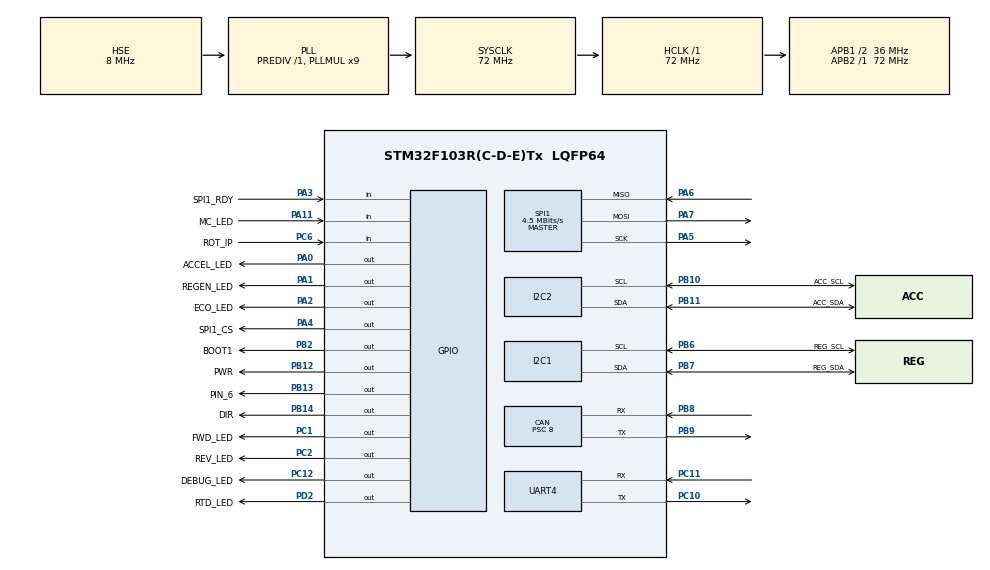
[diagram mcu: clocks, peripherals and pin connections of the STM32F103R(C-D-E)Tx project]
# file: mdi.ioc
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CAN.ABOM=ENABLE
CAN.BS1=CAN_BS1_4TQ
CAN.BS2=CAN_BS2_4TQ
CAN.CalculateBaudRate=500000
CAN.CalculateTimeBit=2000
CAN.CalculateTimeQuantum=222.22222222222223
CAN.NART=ENABLE
CAN.Prescaler=8
CAN.SJW=CAN_SJW_2TQ
Mcu.Family=STM32F1
Mcu.Name=STM32F103R(C-D-E)Tx
Mcu.Package=LQFP64
NVIC.PriorityGroup=NVIC_PRIORITYGROUP_4
NVIC.USB_LP_CAN1_RX0_IRQn=true\:0\:0\:false\:false\:true\:true\:true\:true
PA0-WKUP.GPIO_Label=ACCEL_LED
PA0-WKUP.Signal=GPIO_Output
PA1.GPIO_Label=REGEN_LED
PA1.Signal=GPIO_Output
PA11.GPIO_Label=MC_LED
PA11.Signal=GPIO_Input
PA13.Mode=Trace_Asynchronous_SW
PA13.Signal=SYS_JTMS-SWDIO
PA14.Mode=Trace_Asynchronous_SW
PA14.Signal=SYS_JTCK-SWCLK
PA2.GPIO_Label=ECO_LED
PA2.Signal=GPIO_Output
PA3.GPIO_Label=SPI1_RDY
PA3.Signal=GPIO_Input
PA4.GPIO_Label=SPI1_CS
PA4.PinState=GPIO_PIN_SET
PA4.Signal=GPIO_Output
PA5.Mode=Full_Duplex_Master
PA5.Signal=SPI1_SCK
PA6.Mode=Full_Duplex_Master
PA6.Signal=SPI1_MISO
PA7.Mode=Full_Duplex_Master
PA7.Signal=SPI1_MOSI
PB10.GPIO_Label=ACC_SCL
PB10.Mode=I2C
PB10.Signal=I2C2_SCL
PB11.GPIO_Label=ACC_SDA
PB11.Mode=I2C
PB11.Signal=I2C2_SDA
PB12.GPIO_Label=PWR
PB12.GPIO_ModeDefaultOutputPP=GPIO_MODE_OUTPUT_OD
PB12.GPIO_PuPd=GPIO_NOPULL
PB12.Signal=GPIO_Output
PB13.GPIO_Label=PIN_6
PB13.Signal=GPIO_Output
PB14.GPIO_Label=DIR
PB14.GPIO_ModeDefaultOutputPP=GPIO_MODE_OUTPUT_OD
PB14.GPIO_PuPd=GPIO_NOPULL
PB14.Signal=GPIO_Output
PB2.GPIO_Label=BOOT1
PB2.Signal=GPIO_Output
PB3.Mode=Trace_Asynchronous_SW
PB3.Signal=SYS_JTDO-TRACESWO
PB6.GPIO_Label=REG_SCL
PB6.Mode=I2C
PB6.Signal=I2C1_SCL
PB7.GPIO_Label=REG_SDA
PB7.Mode=I2C
PB7.Signal=I2C1_SDA
PB8.Mode=CAN_Activate
PB8.Signal=CAN_RX
PB9.Mode=CAN_Activate
PB9.Signal=CAN_TX
PC1.GPIO_Label=FWD_LED
PC1.Signal=GPIO_Output
PC10.Mode=Asynchronous
PC10.Signal=UART4_TX
PC11.Mode=Asynchronous
PC11.Signal=UART4_RX
PC12.GPIO_Label=DEBUG_LED
PC12.Signal=GPIO_Output
PC2.GPIO_Label=REV_LED
PC2.Signal=GPIO_Output
PC6.GPIO_Label=ROT_IP
PC6.Signal=GPIO_Input
PD0-OSC_IN.Mode=HSE-External-Oscillator
PD0-OSC_IN.Signal=RCC_OSC_IN
PD1-OSC_OUT.Mode=HSE-External-Oscillator
PD1-OSC_OUT.Signal=RCC_OSC_OUT
PD2.GPIO_Label=RTD_LED
PD2.Signal=GPIO_Output
ProjectManager.HeapSize=0x200
ProjectManager.StackSize=0x400
ProjectManager.TargetToolchain=CMake
RCC.AHBFreq_Value=72000000
RCC.APB1CLKDivider=RCC_HCLK_DIV2
RCC.APB1Freq_Value=36000000
RCC.APB1TimFreq_Value=72000000
RCC.APB2Freq_Value=72000000
RCC.APB2TimFreq_Value=72000000
RCC.HCLKFreq_Value=72000000
RCC.PLLMUL=RCC_PLL_MUL9
RCC.PLLSourceVirtual=RCC_PLLSOURCE_HSE
RCC.SYSCLKFreq_VALUE=72000000
RCC.SYSCLKSource=RCC_SYSCLKSOURCE_PLLCLK
RCC.USBFreq_Value=72000000
SPI1.BaudRatePrescaler=SPI_BAUDRATEPRESCALER_16
SPI1.CLKPhase=SPI_PHASE_2EDGE
SPI1.CLKPolarity=SPI_POLARITY_LOW
SPI1.CalculateBaudRate=4.5 MBits/s
SPI1.Direction=SPI_DIRECTION_2LINES
SPI1.Mode=SPI_MODE_MASTER
SPI1.VirtualType=VM_MASTER
UART4.VirtualMode=Asynchronous
VP_IWDG_VS_IWDG.Mode=IWDG_Activate
board=custom

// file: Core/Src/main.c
/* USER CODE BEGIN Header */
/**
  ******************************************************************************
  * @file           : main.c
  * @brief          : Main program body
  ******************************************************************************
  * @attention
  *
  * Copyright (c) 2026 STMicroelectronics.
  * All rights reserved.
  *
  * This software is licensed under terms that can be found in the LICENSE file
  * in the root directory of this software component.
  * If no LICENSE file comes with this software, it is provided AS-IS.
  *
  ******************************************************************************
  */
/* USER CODE END Header */
#include "main.h"

/* USER CODE BEGIN Includes */
#include "tasks.h"
#include "iwdg_common.h"

/* USER CODE END Includes */

CAN_HandleTypeDef hcan;

I2C_HandleTypeDef hi2c1;
I2C_HandleTypeDef hi2c2;

IWDG_HandleTypeDef hiwdg;

SPI_HandleTypeDef hspi1;

UART_HandleTypeDef huart4;

void SystemClock_Config(void);
static void MX_GPIO_Init(void);
static void MX_CAN_Init(void);
static void MX_I2C1_Init(void);
static void MX_I2C2_Init(void);
static void MX_SPI1_Init(void);
static void MX_UART4_Init(void);
static void MX_IWDG_Init(void);

int main(void)
{

  /* MCU Configuration--------------------------------------------------------*/

  /* Reset of all peripherals, Initializes the Flash interface and the Systick. */
  HAL_Init();

  /* Configure the system clock */
  SystemClock_Config();

  /* Initialize all configured peripherals */
  MX_GPIO_Init();
  MX_CAN_Init();
  MX_I2C1_Init();
  MX_I2C2_Init();
  MX_SPI1_Init();
  MX_UART4_Init();
  #ifndef DEBUG
  MX_IWDG_Init();
  #endif
  /* USER CODE BEGIN 2 */
  AppMain();
  /* USER CODE END 2 */

  /* Infinite loop */
  while (1)
  {

  }
}

void SystemClock_Config(void)
{
  RCC_OscInitTypeDef RCC_OscInitStruct = {0};
  RCC_ClkInitTypeDef RCC_ClkInitStruct = {0};

  /** Initializes the RCC Oscillators according to the specified parameters
  * in the RCC_OscInitTypeDef structure.
  */
  RCC_OscInitStruct.OscillatorType = RCC_OSCILLATORTYPE_LSI|RCC_OSCILLATORTYPE_HSE;
  RCC_OscInitStruct.HSEState = RCC_HSE_ON;
  RCC_OscInitStruct.HSEPredivValue = RCC_HSE_PREDIV_DIV1;
  RCC_OscInitStruct.HSIState = RCC_HSI_ON;
  RCC_OscInitStruct.LSIState = RCC_LSI_ON;
  RCC_OscInitStruct.PLL.PLLState = RCC_PLL_ON;
  RCC_OscInitStruct.PLL.PLLSource = RCC_PLLSOURCE_HSE;
  RCC_OscInitStruct.PLL.PLLMUL = RCC_PLL_MUL9;
  if (HAL_RCC_OscConfig(&RCC_OscInitStruct) != HAL_OK)
  {
    Error_Handler();
  }

  /** Initializes the CPU, AHB and APB buses clocks
  */
  RCC_ClkInitStruct.ClockType = RCC_CLOCKTYPE_HCLK|RCC_CLOCKTYPE_SYSCLK
                              |RCC_CLOCKTYPE_PCLK1|RCC_CLOCKTYPE_PCLK2;
  RCC_ClkInitStruct.SYSCLKSource = RCC_SYSCLKSOURCE_PLLCLK;
  RCC_ClkInitStruct.AHBCLKDivider = RCC_SYSCLK_DIV1;
  RCC_ClkInitStruct.APB1CLKDivider = RCC_HCLK_DIV2;
  RCC_ClkInitStruct.APB2CLKDivider = RCC_HCLK_DIV1;

  if (HAL_RCC_ClockConfig(&RCC_ClkInitStruct, FLASH_LATENCY_2) != HAL_OK)
  {
    Error_Handler();
  }
}

static void MX_CAN_Init(void)
{

  hcan.Instance = CAN1;
  hcan.Init.Prescaler = 8;
  hcan.Init.Mode = CAN_MODE_NORMAL;
  hcan.Init.SyncJumpWidth = CAN_SJW_2TQ;
  hcan.Init.TimeSeg1 = CAN_BS1_4TQ;
  hcan.Init.TimeSeg2 = CAN_BS2_4TQ;
  hcan.Init.TimeTriggeredMode = DISABLE;
  hcan.Init.AutoBusOff = ENABLE;
  hcan.Init.AutoWakeUp = DISABLE;
  hcan.Init.AutoRetransmission = ENABLE;
  hcan.Init.ReceiveFifoLocked = DISABLE;
  hcan.Init.TransmitFifoPriority = DISABLE;
  if (HAL_CAN_Init(&hcan) != HAL_OK)
  {
    Error_Handler();
  }

}

static void MX_I2C1_Init(void)
{

  hi2c1.Instance = I2C1;
  hi2c1.Init.ClockSpeed = 100000;
  hi2c1.Init.DutyCycle = I2C_DUTYCYCLE_2;
  hi2c1.Init.OwnAddress1 = 0;
  hi2c1.Init.AddressingMode = I2C_ADDRESSINGMODE_7BIT;
  hi2c1.Init.DualAddressMode = I2C_DUALADDRESS_DISABLE;
  hi2c1.Init.OwnAddress2 = 0;
  hi2c1.Init.GeneralCallMode = I2C_GENERALCALL_DISABLE;
  hi2c1.Init.NoStretchMode = I2C_NOSTRETCH_DISABLE;
  if (HAL_I2C_Init(&hi2c1) != HAL_OK)
  {
    Error_Handler();
  }

}

static void MX_I2C2_Init(void)
{

  hi2c2.Instance = I2C2;
  hi2c2.Init.ClockSpeed = 100000;
  hi2c2.Init.DutyCycle = I2C_DUTYCYCLE_2;
  hi2c2.Init.OwnAddress1 = 0;
  hi2c2.Init.AddressingMode = I2C_ADDRESSINGMODE_7BIT;
  hi2c2.Init.DualAddressMode = I2C_DUALADDRESS_DISABLE;
  hi2c2.Init.OwnAddress2 = 0;
  hi2c2.Init.GeneralCallMode = I2C_GENERALCALL_DISABLE;
  hi2c2.Init.NoStretchMode = I2C_NOSTRETCH_DISABLE;
  if (HAL_I2C_Init(&hi2c2) != HAL_OK)
  {
    Error_Handler();
  }

}

static void MX_IWDG_Init(void)
{

  hiwdg.Instance = IWDG;
  hiwdg.Init.Prescaler = IWDG_PRESCALER_4;
  hiwdg.Init.Reload = 4095;
  if (HAL_IWDG_Init(&hiwdg) != HAL_OK)
  {
    Error_Handler();
  }

}

static void MX_SPI1_Init(void)
{

  /* SPI1 parameter configuration*/
  hspi1.Instance = SPI1;
  hspi1.Init.Mode = SPI_MODE_MASTER;
  hspi1.Init.Direction = SPI_DIRECTION_2LINES;
  hspi1.Init.DataSize = SPI_DATASIZE_8BIT;
  hspi1.Init.CLKPolarity = SPI_POLARITY_LOW;
  hspi1.Init.CLKPhase = SPI_PHASE_2EDGE;
  hspi1.Init.NSS = SPI_NSS_SOFT;
  hspi1.Init.BaudRatePrescaler = SPI_BAUDRATEPRESCALER_16;
  hspi1.Init.FirstBit = SPI_FIRSTBIT_MSB;
  hspi1.Init.TIMode = SPI_TIMODE_DISABLE;
  hspi1.Init.CRCCalculation = SPI_CRCCALCULATION_DISABLE;
  hspi1.Init.CRCPolynomial = 10;
  if (HAL_SPI_Init(&hspi1) != HAL_OK)
  {
    Error_Handler();
  }

}

static void MX_UART4_Init(void)
{

  huart4.Instance = UART4;
  huart4.Init.BaudRate = 115200;
  huart4.Init.WordLength = UART_WORDLENGTH_8B;
  huart4.Init.StopBits = UART_STOPBITS_1;
  huart4.Init.Parity = UART_PARITY_NONE;
  huart4.Init.Mode = UART_MODE_TX_RX;
  huart4.Init.HwFlowCtl = UART_HWCONTROL_NONE;
  huart4.Init.OverSampling = UART_OVERSAMPLING_16;
  if (HAL_UART_Init(&huart4) != HAL_OK)
  {
    Error_Handler();
  }

}

static void MX_GPIO_Init(void)
{
  GPIO_InitTypeDef GPIO_InitStruct = {0};

  /* GPIO Ports Clock Enable */
  __HAL_RCC_GPIOD_CLK_ENABLE();
  __HAL_RCC_GPIOC_CLK_ENABLE();
  __HAL_RCC_GPIOA_CLK_ENABLE();
  __HAL_RCC_GPIOB_CLK_ENABLE();

  /*Configure GPIO pin Output Level */
  HAL_GPIO_WritePin(GPIOC, FWD_LED_Pin|REV_LED_Pin|DEBUG_LED_Pin, GPIO_PIN_RESET);

  /*Configure GPIO pin Output Level */
  HAL_GPIO_WritePin(GPIOA, ACCEL_LED_Pin|REGEN_LED_Pin|ECO_LED_Pin, GPIO_PIN_RESET);

  /*Configure GPIO pin Output Level */
  HAL_GPIO_WritePin(SPI1_CS_GPIO_Port, SPI1_CS_Pin, GPIO_PIN_SET);

  /*Configure GPIO pin Output Level */
  HAL_GPIO_WritePin(GPIOB, BOOT1_Pin|PWR_Pin|PIN_6_Pin|DIR_Pin, GPIO_PIN_RESET);

  /*Configure GPIO pin Output Level */
  HAL_GPIO_WritePin(RTD_LED_GPIO_Port, RTD_LED_Pin, GPIO_PIN_RESET);

  /*Configure GPIO pins : FWD_LED_Pin REV_LED_Pin DEBUG_LED_Pin */
  GPIO_InitStruct.Pin = FWD_LED_Pin|REV_LED_Pin|DEBUG_LED_Pin;
  GPIO_InitStruct.Mode = GPIO_MODE_OUTPUT_PP;
  GPIO_InitStruct.Pull = GPIO_NOPULL;
  GPIO_InitStruct.Speed = GPIO_SPEED_FREQ_LOW;
  HAL_GPIO_Init(GPIOC, &GPIO_InitStruct);

  /*Configure GPIO pins : ACCEL_LED_Pin REGEN_LED_Pin ECO_LED_Pin SPI1_CS_Pin */
  GPIO_InitStruct.Pin = ACCEL_LED_Pin|REGEN_LED_Pin|ECO_LED_Pin|SPI1_CS_Pin;
  GPIO_InitStruct.Mode = GPIO_MODE_OUTPUT_PP;
  GPIO_InitStruct.Pull = GPIO_NOPULL;
  GPIO_InitStruct.Speed = GPIO_SPEED_FREQ_LOW;
  HAL_GPIO_Init(GPIOA, &GPIO_InitStruct);

  /*Configure GPIO pins : SPI1_RDY_Pin MC_LED_Pin */
  GPIO_InitStruct.Pin = SPI1_RDY_Pin|MC_LED_Pin;
  GPIO_InitStruct.Mode = GPIO_MODE_INPUT;
  GPIO_InitStruct.Pull = GPIO_NOPULL;
  HAL_GPIO_Init(GPIOA, &GPIO_InitStruct);

  /*Configure GPIO pins : BOOT1_Pin PIN_6_Pin */
  GPIO_InitStruct.Pin = BOOT1_Pin|PIN_6_Pin;
  GPIO_InitStruct.Mode = GPIO_MODE_OUTPUT_PP;
  GPIO_InitStruct.Pull = GPIO_NOPULL;
  GPIO_InitStruct.Speed = GPIO_SPEED_FREQ_LOW;
  HAL_GPIO_Init(GPIOB, &GPIO_InitStruct);

  /*Configure GPIO pins : PWR_Pin DIR_Pin */
  GPIO_InitStruct.Pin = PWR_Pin|DIR_Pin;
  GPIO_InitStruct.Mode = GPIO_MODE_OUTPUT_OD;
  GPIO_InitStruct.Pull = GPIO_NOPULL;
  GPIO_InitStruct.Speed = GPIO_SPEED_FREQ_LOW;
  HAL_GPIO_Init(GPIOB, &GPIO_InitStruct);

  /*Configure GPIO pin : ROT_IP_Pin */
  GPIO_InitStruct.Pin = ROT_IP_Pin;
  GPIO_InitStruct.Mode = GPIO_MODE_INPUT;
  GPIO_InitStruct.Pull = GPIO_NOPULL;
  HAL_GPIO_Init(ROT_IP_GPIO_Port, &GPIO_InitStruct);

  /*Configure GPIO pin : RTD_LED_Pin */
  GPIO_InitStruct.Pin = RTD_LED_Pin;
  GPIO_InitStruct.Mode = GPIO_MODE_OUTPUT_PP;
  GPIO_InitStruct.Pull = GPIO_NOPULL;
  GPIO_InitStruct.Speed = GPIO_SPEED_FREQ_LOW;
  HAL_GPIO_Init(RTD_LED_GPIO_Port, &GPIO_InitStruct);

}

void Error_Handler(void)
{
  __disable_irq();
  while (1)
  {
  }
}
